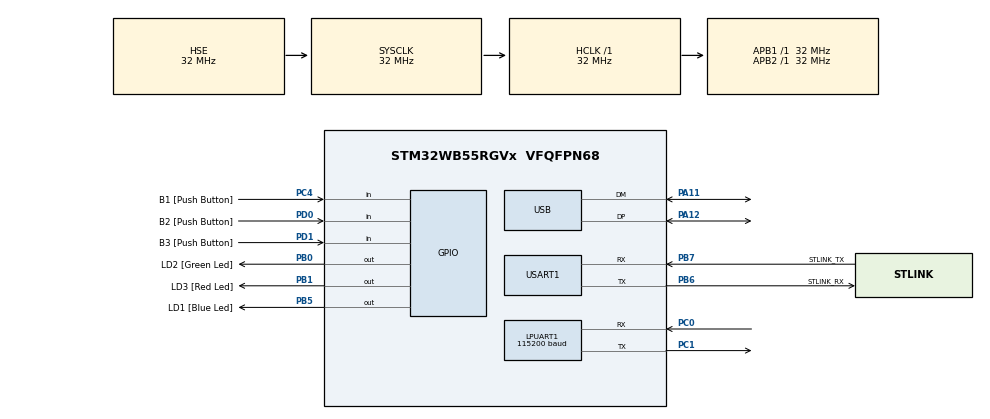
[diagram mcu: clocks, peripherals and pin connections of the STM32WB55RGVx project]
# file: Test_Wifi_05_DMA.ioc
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Dma.LPUART1_RX.0.Direction=DMA_PERIPH_TO_MEMORY
Dma.LPUART1_RX.0.EventEnable=DISABLE
Dma.LPUART1_RX.0.Instance=DMA1_Channel2
Dma.LPUART1_RX.0.MemDataAlignment=DMA_MDATAALIGN_BYTE
Dma.LPUART1_RX.0.MemInc=DMA_MINC_ENABLE
Dma.LPUART1_RX.0.Mode=DMA_CIRCULAR
Dma.LPUART1_RX.0.PeriphDataAlignment=DMA_PDATAALIGN_BYTE
Dma.LPUART1_RX.0.PeriphInc=DMA_PINC_DISABLE
Dma.LPUART1_RX.0.Polarity=HAL_DMAMUX_REQ_GEN_RISING
Dma.LPUART1_RX.0.Priority=DMA_PRIORITY_LOW
Dma.LPUART1_RX.0.RequestNumber=1
Dma.LPUART1_RX.0.SignalID=NONE
Dma.LPUART1_RX.0.SyncEnable=DISABLE
Dma.LPUART1_RX.0.SyncPolarity=HAL_DMAMUX_SYNC_NO_EVENT
Dma.LPUART1_RX.0.SyncRequestNumber=1
Dma.LPUART1_RX.0.SyncSignalID=NONE
Dma.Request0=LPUART1_RX
LPUART1.BaudRate=115200
Mcu.Family=STM32WB
Mcu.Name=STM32WB55RGVx
Mcu.Package=VFQFPN68
NVIC.DMA1_Channel2_IRQn=true\:0\:0\:false\:false\:true\:false\:true\:true
NVIC.LPUART1_IRQn=true\:0\:0\:false\:false\:true\:true\:true\:true
NVIC.PriorityGroup=NVIC_PRIORITYGROUP_4
OSC_IN.Mode=HSE-External-Oscillator
OSC_IN.Signal=RCC_OSC_IN
OSC_OUT.Mode=HSE-External-Oscillator
OSC_OUT.Signal=RCC_OSC_OUT
PA11.Mode=Device
PA11.Signal=USB_DM
PA12.Mode=Device
PA12.Signal=USB_DP
PA13.GPIO_Label=JTMS
PA13.Mode=Trace_Asynchronous_SW
PA13.Signal=SYS_JTMS-SWDIO
PA14.GPIO_Label=JTCK
PA14.Mode=Trace_Asynchronous_SW
PA14.Signal=SYS_JTCK-SWCLK
PB0.GPIO_Label=LD2 [Green Led]
PB0.Signal=GPIO_Output
PB1.GPIO_Label=LD3 [Red Led]
PB1.Signal=GPIO_Output
PB3.GPIO_Label=JTDO
PB3.Mode=Trace_Asynchronous_SW
PB3.Signal=SYS_JTDO-SWO
PB5.GPIO_Label=LD1 [Blue Led]
PB5.Signal=GPIO_Output
PB6.GPIO_Label=STLINK_RX
PB6.GPIO_PuPd=GPIO_PULLUP
PB6.Mode=Asynchronous
PB6.Signal=USART1_TX
PB7.GPIO_Label=STLINK_TX
PB7.GPIO_PuPd=GPIO_PULLUP
PB7.Mode=Asynchronous
PB7.Signal=USART1_RX
PC0.Mode=Asynchronous
PC0.Signal=LPUART1_RX
PC1.Mode=Asynchronous
PC1.Signal=LPUART1_TX
PC13.Mode=SYS_WakeUp1
PC13.Signal=SYS_WKUP2
PC14-OSC32_IN.Mode=LSE-External-Oscillator
PC14-OSC32_IN.Signal=RCC_OSC32_IN
PC15-OSC32_OUT.Mode=LSE-External-Oscillator
PC15-OSC32_OUT.Signal=RCC_OSC32_OUT
PC4.GPIO_Label=B1 [Push Button]
PC4.Signal=GPIO_Input
PD0.GPIO_Label=B2 [Push Button]
PD0.Signal=GPIO_Input
PD1.GPIO_Label=B3 [Push Button]
PD1.Signal=GPIO_Input
ProjectManager.HeapSize=0x200
ProjectManager.StackSize=0x400
ProjectManager.TargetToolchain=STM32CubeIDE
RCC.ADCFreq_Value=48000000
RCC.AHBFreq_Value=32000000
RCC.APB1Freq_Value=32000000
RCC.APB1TimFreq_Value=32000000
RCC.APB2Freq_Value=32000000
RCC.APB2TimFreq_Value=32000000
RCC.APB3Freq_Value=16000000
RCC.CortexFreq_Value=32000000
RCC.HCLKFreq_Value=32000000
RCC.HSE_VALUE=32000000
RCC.HSI48_VALUE=48000000
RCC.HSI_VALUE=16000000
RCC.PLLN=32
RCC.PLLSAI1N=24
RCC.SMPSCLockSelectionVirtual=RCC_SMPSCLKSOURCE_HSI
RCC.SMPSCLockSelectionVirtualVirtual=RCC_SMPSCLKSOURCE_HSI
RCC.SMPSDivider=1
RCC.SYSCLKFreq_VALUE=32000000
RCC.SYSCLKSource=RCC_SYSCLKSOURCE_HSE
RCC.USBFreq_Value=48000000
RCC.VCOOutputFreq_Value=128000000
USART1.VirtualMode-Asynchronous=VM_ASYNC
USART1.WordLength=WORDLENGTH_7B
board=NUCLEO-WB55RG

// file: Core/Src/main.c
/* USER CODE BEGIN Header */
/**
  ******************************************************************************
  * @file           : main.c
  * @brief          : Main program body
  ******************************************************************************
  * @attention
  *
  * Copyright (c) 2023 STMicroelectronics.
  * All rights reserved.
  *
  * This software is licensed under terms that can be found in the LICENSE file
  * in the root directory of this software component.
  * If no LICENSE file comes with this software, it is provided AS-IS.
  *
  ******************************************************************************
  */
/* USER CODE END Header */
#include "main.h"
#include "dma.h"
#include "usart.h"
#include "usb.h"
#include "gpio.h"

/* USER CODE BEGIN Includes */
#include "wifi.h"
#include "stdlib.h"
#include "stdio.h"
#include "string.h"
/* USER CODE END Includes */

void SystemClock_Config(void);
void PeriphCommonClock_Config(void);
/* USER CODE BEGIN PFP */
int _write(int file, char *ptr, int len);
/* USER CODE END PFP */

/* USER CODE BEGIN 0 */
int _write(int file, char *ptr, int len)
{
int DataIdx;
for (DataIdx = 0; DataIdx < len; DataIdx++)
{
//__io_putchar(*ptr++);
ITM_SendChar(*ptr++);
}
return len;
}
/* USER CODE END 0 */

int main(void)
{

  /* MCU Configuration--------------------------------------------------------*/

  /* Reset of all peripherals, Initializes the Flash interface and the Systick. */
  HAL_Init();

  /* Configure the system clock */
  SystemClock_Config();

/* Configure the peripherals common clocks */
  PeriphCommonClock_Config();

  /* Initialize all configured peripherals */
  MX_GPIO_Init();
  MX_DMA_Init();
  MX_USART1_UART_Init();
  MX_USB_PCD_Init();
  MX_LPUART1_UART_Init();
  /* USER CODE BEGIN 2 */
  Wifi_Init();
  /* USER CODE END 2 */

  /* Infinite loop */
  while (1)
  {

    /* USER CODE BEGIN 3 */
	  //printf("process\n");
	  //HAL_Delay(1000);
  }
  /* USER CODE END 3 */
}

void SystemClock_Config(void)
{
  RCC_OscInitTypeDef RCC_OscInitStruct = {0};
  RCC_ClkInitTypeDef RCC_ClkInitStruct = {0};

  /** Macro to configure the PLL multiplication factor
  */
  __HAL_RCC_PLL_PLLM_CONFIG(RCC_PLLM_DIV1);

  /** Macro to configure the PLL clock source
  */
  __HAL_RCC_PLL_PLLSOURCE_CONFIG(RCC_PLLSOURCE_MSI);

  /** Configure LSE Drive Capability
  */
  HAL_PWR_EnableBkUpAccess();
  __HAL_RCC_LSEDRIVE_CONFIG(RCC_LSEDRIVE_MEDIUMHIGH);

  /** Configure the main internal regulator output voltage
  */
  __HAL_PWR_VOLTAGESCALING_CONFIG(PWR_REGULATOR_VOLTAGE_SCALE1);

  /** Initializes the RCC Oscillators according to the specified parameters
  * in the RCC_OscInitTypeDef structure.
  */
  RCC_OscInitStruct.OscillatorType = RCC_OSCILLATORTYPE_HSI|RCC_OSCILLATORTYPE_HSE
                              |RCC_OSCILLATORTYPE_LSE|RCC_OSCILLATORTYPE_MSI;
  RCC_OscInitStruct.HSEState = RCC_HSE_ON;
  RCC_OscInitStruct.LSEState = RCC_LSE_ON;
  RCC_OscInitStruct.HSIState = RCC_HSI_ON;
  RCC_OscInitStruct.MSIState = RCC_MSI_ON;
  RCC_OscInitStruct.HSICalibrationValue = RCC_HSICALIBRATION_DEFAULT;
  RCC_OscInitStruct.MSICalibrationValue = RCC_MSICALIBRATION_DEFAULT;
  RCC_OscInitStruct.MSIClockRange = RCC_MSIRANGE_6;
  RCC_OscInitStruct.PLL.PLLState = RCC_PLL_NONE;
  if (HAL_RCC_OscConfig(&RCC_OscInitStruct) != HAL_OK)
  {
    Error_Handler();
  }

  /** Configure the SYSCLKSource, HCLK, PCLK1 and PCLK2 clocks dividers
  */
  RCC_ClkInitStruct.ClockType = RCC_CLOCKTYPE_HCLK4|RCC_CLOCKTYPE_HCLK2
                              |RCC_CLOCKTYPE_HCLK|RCC_CLOCKTYPE_SYSCLK
                              |RCC_CLOCKTYPE_PCLK1|RCC_CLOCKTYPE_PCLK2;
  RCC_ClkInitStruct.SYSCLKSource = RCC_SYSCLKSOURCE_HSE;
  RCC_ClkInitStruct.AHBCLKDivider = RCC_SYSCLK_DIV1;
  RCC_ClkInitStruct.APB1CLKDivider = RCC_HCLK_DIV1;
  RCC_ClkInitStruct.APB2CLKDivider = RCC_HCLK_DIV1;
  RCC_ClkInitStruct.AHBCLK2Divider = RCC_SYSCLK_DIV1;
  RCC_ClkInitStruct.AHBCLK4Divider = RCC_SYSCLK_DIV1;

  if (HAL_RCC_ClockConfig(&RCC_ClkInitStruct, FLASH_LATENCY_1) != HAL_OK)
  {
    Error_Handler();
  }

  /** Enable MSI Auto calibration
  */
  HAL_RCCEx_EnableMSIPLLMode();
}

void PeriphCommonClock_Config(void)
{
  RCC_PeriphCLKInitTypeDef PeriphClkInitStruct = {0};

  /** Initializes the peripherals clock
  */
  PeriphClkInitStruct.PeriphClockSelection = RCC_PERIPHCLK_SMPS;
  PeriphClkInitStruct.SmpsClockSelection = RCC_SMPSCLKSOURCE_HSI;
  PeriphClkInitStruct.SmpsDivSelection = RCC_SMPSCLKDIV_RANGE0;

  if (HAL_RCCEx_PeriphCLKConfig(&PeriphClkInitStruct) != HAL_OK)
  {
    Error_Handler();
  }
}

void Error_Handler(void)
{
  __disable_irq();
  while (1)
  {
  }
}
